# ATmega164PA register map
Vendor: Atmel; File version: 1.0
CPU: other r0p0, little endian, no MPU, no FPU, 4 interrupt priority bits
Registers are 8-bit, read-write, reset 0x0 unless marked. A register's access mark holds for its fields unless they carry their own. Offsets are from the block's base; [hi:lo] are bit positions.

## TC1 — Timer/Counter, 16-bit
Base 0x00800036
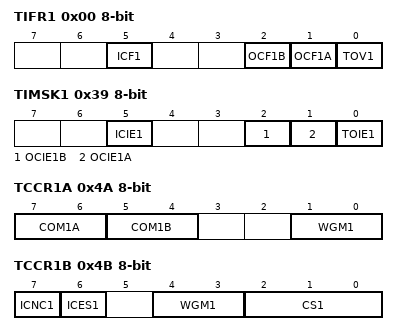
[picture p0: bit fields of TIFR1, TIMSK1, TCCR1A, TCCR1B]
0x00 TIFR1 — Timer/Counter Interrupt Flag register (read-only for debugger)
  [5] ICF1 — Timer/Counter1 Input Capture Flag
  [2] OCF1B — Timer/Counter1 Output Compare B Match Flag
  [1] OCF1A — Timer/Counter1 Output Compare A Match Flag
  [0] TOV1 — Timer/Counter1 Overflow Flag
0x39 TIMSK1 — Timer/Counter1 Interrupt Mask Register
  [5] ICIE1 — Timer/Counter1 Input Capture Interrupt Enable
  [2] OCIE1B — Timer/Counter1 Output Compare B Match Interrupt Enable
  [1] OCIE1A — Timer/Counter1 Output Compare A Match Interrupt Enable
  [0] TOIE1 — Timer/Counter1 Overflow Interrupt Enable
0x4A TCCR1A — Timer/Counter1 Control Register A
  [7:6] COM1A — Compare Output Mode 1A, bits
  [5:4] COM1B — Compare Output Mode 1B, bits
  [1:0] WGM1 — Pulse Width Modulator Select Bits
0x4B TCCR1B — Timer/Counter1 Control Register B
  [7] ICNC1 — Input Capture 1 Noise Canceler
  [6] ICES1 — Input Capture 1 Edge Select
  [4:3] WGM1 — Waveform Generation Mode Bits
  [2:0] CS1 — Clock Select1 bits
    0=NO_CLOCK_SOURCE_STOPPED; 1=RUNNING_NO_PRESCALING; 2=RUNNING_CLK_8; 3=RUNNING_CLK_64; 4=RUNNING_CLK_256; 5=RUNNING_CLK_1024; 6=RUNNING_EXTCLK_TN_FALLING_EDGE; 7=RUNNING_EXTCLK_TN_RISING_EDGE
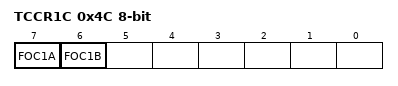
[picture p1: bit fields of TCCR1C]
0x4C TCCR1C — Timer/Counter1 Control Register C (write-only for debugger)
  [7] FOC1A — Force Output Compare for Channel A
  [6] FOC1B — Force Output Compare for Channel B
0x4E TCNT1 16-bit (reset mask 0xFF) — Timer/Counter1 Bytes
0x50 ICR1 16-bit (reset mask 0xFF) — Timer/Counter1 Input Capture Register Bytes
0x52 OCR1A 16-bit (reset mask 0xFF) — Timer/Counter1 Output Compare Register A Bytes
0x54 OCR1B 16-bit (reset mask 0xFF) — Timer/Counter1 Output Compare Register B Bytes

## TC2 — Timer/Counter, 8-bit Async
Base 0x00800037
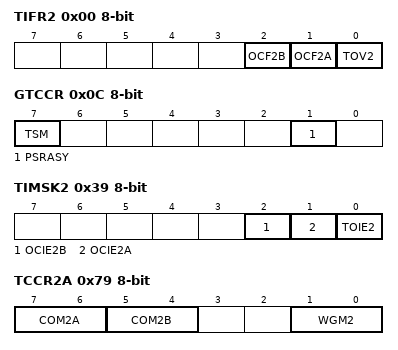
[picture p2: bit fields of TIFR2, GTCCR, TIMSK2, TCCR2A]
0x00 TIFR2 — Timer/Counter Interrupt Flag Register (read-only for debugger)
  [2] OCF2B — Output Compare Flag 2B
  [1] OCF2A — Output Compare Flag 2A
  [0] TOV2 — Timer/Counter2 Overflow Flag
0x0C GTCCR — General Timer Counter Control register
  [7] TSM — Timer/Counter Synchronization Mode
  [1] PSRASY — Prescaler Reset Timer/Counter2
0x39 TIMSK2 — Timer/Counter Interrupt Mask register
  [2] OCIE2B — Timer/Counter2 Output Compare Match B Interrupt Enable
  [1] OCIE2A — Timer/Counter2 Output Compare Match A Interrupt Enable
  [0] TOIE2 — Timer/Counter2 Overflow Interrupt Enable
0x79 TCCR2A — Timer/Counter2 Control Register A
  [7:6] COM2A — Compare Output Mode bits
  [5:4] COM2B — Compare Output Mode bits
  [1:0] WGM2 — Waveform Generation Mode
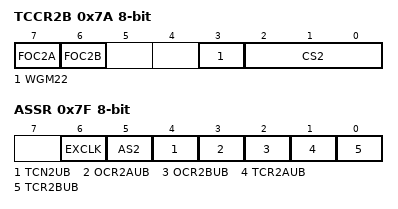
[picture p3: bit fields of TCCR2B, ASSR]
0x7A TCCR2B — Timer/Counter2 Control Register B
  [7] FOC2A — Force Output Compare A
  [6] FOC2B — Force Output Compare B
  [3] WGM22 — Waveform Generation Mode
  [2:0] CS2 — Clock Select bits
    0=NO_CLOCK_SOURCE_STOPPED; 1=RUNNING_NO_PRESCALING; 2=RUNNING_CLK_8; 3=RUNNING_CLK_32; 4=RUNNING_CLK_64; 5=RUNNING_CLK_128; 6=RUNNING_CLK_256; 7=RUNNING_CLK_1024
0x7B TCNT2 — Timer/Counter2
0x7C OCR2A — Timer/Counter2 Output Compare Register A
0x7D OCR2B — Timer/Counter2 Output Compare Register B
0x7F ASSR — Asynchronous Status Register
  [6] EXCLK — Enable External Clock Input
  [5] AS2 — Asynchronous Timer/Counter2
  [4] TCN2UB — Timer/Counter2 Update Busy
  [3] OCR2AUB — Output Compare Register2 Update Busy
  [2] OCR2BUB — Output Compare Register 2 Update Busy
  [1] TCR2AUB — Timer/Counter Control Register2 Update Busy
  [0] TCR2BUB — Timer/Counter Control Register2 Update Busy

## TWI — Two Wire Serial Interface
Base 0x008000B8
0x00 TWBR — TWI Bit Rate register
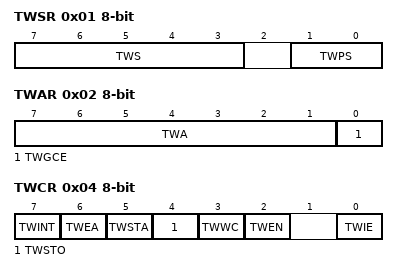
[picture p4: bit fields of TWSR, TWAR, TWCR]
0x01 TWSR — TWI Status Register
  [7:3] TWS — TWI Status
  [1:0] TWPS — TWI Prescaler
    0=1; 1=4; 2=16; 3=64
0x02 TWAR — TWI (Slave) Address register
  [7:1] TWA — TWI (Slave) Address register Bits
  [0] TWGCE — TWI General Call Recognition Enable Bit
0x03 TWDR — TWI Data register
0x04 TWCR — TWI Control Register (read-only for debugger)
  [7] TWINT — TWI Interrupt Flag
  [6] TWEA — TWI Enable Acknowledge Bit
  [5] TWSTA — TWI Start Condition Bit
  [4] TWSTO — TWI Stop Condition Bit
  [3] TWWC — TWI Write Collision Flag
  [2] TWEN — TWI Enable Bit
  [0] TWIE — TWI Interrupt Enable
0x05 TWAMR — TWI (Slave) Address Mask Register
  [7:1] TWAM

## USART0 — USART
Base 0x008000C0
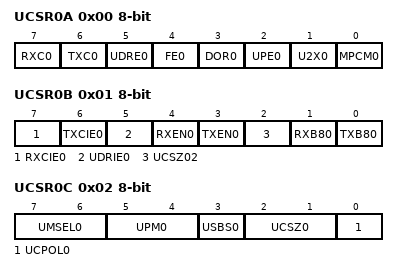
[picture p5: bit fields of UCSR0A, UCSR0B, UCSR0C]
0x00 UCSR0A — USART Control and Status Register A (read-only for debugger)
  [7] RXC0 ro — USART Receive Complete
  [6] TXC0 — USART Transmit Complete
  [5] UDRE0 ro — USART Data Register Empty
  [4] FE0 ro — Framing Error
  [3] DOR0 ro — Data overRun
  [2] UPE0 ro — Parity Error
  [1] U2X0 — Double the USART transmission speed
  [0] MPCM0 — Multi-processor Communication Mode
0x01 UCSR0B — USART Control and Status Register B
  [7] RXCIE0 — RX Complete Interrupt Enable
  [6] TXCIE0 — TX Complete Interrupt Enable
  [5] UDRIE0 — USART Data register Empty Interrupt Enable
  [4] RXEN0 — Receiver Enable
  [3] TXEN0 — Transmitter Enable
  [2] UCSZ02 — Character Size
  [1] RXB80 — Receive Data Bit 8
  [0] TXB80 — Transmit Data Bit 8
0x02 UCSR0C — USART Control and Status Register C
  [7:6] UMSEL0 — USART Mode Select
    0=ASYNCHRONOUS_USART; 1=SYNCHRONOUS_USART; 3=MASTER_SPI
  [5:4] UPM0 — Parity Mode Bits
    0=DISABLED; 2=ENABLED_EVEN_PARITY; 3=ENABLED_ODD_PARITY
  [3] USBS0 — Stop Bit Select
    0=1_BIT; 1=2_BIT
  [2:1] UCSZ0 — Character Size
  [0] UCPOL0 — Clock Polarity
0x04 UBRR0 16-bit (reset mask 0xFF) — USART Baud Rate Register Bytes
0x06 UDR0 — USART I/O Data Register (write-only for debugger)

## USART1 — USART
Base 0x008000C8
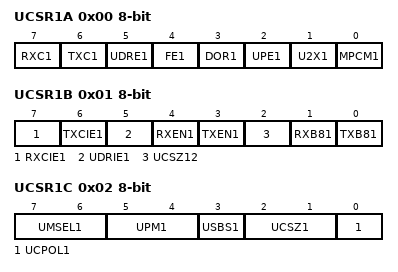
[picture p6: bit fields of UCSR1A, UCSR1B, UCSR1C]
0x00 UCSR1A — USART Control and Status Register A (read-only for debugger)
  [7] RXC1 — USART Receive Complete
  [6] TXC1 — USART Transmit Complete
  [5] UDRE1 — USART Data Register Empty
  [4] FE1 — Framing Error
  [3] DOR1 — Data overRun
  [2] UPE1 — Parity Error
  [1] U2X1 — Double the USART transmission speed
  [0] MPCM1 — Multi-processor Communication Mode
0x01 UCSR1B — USART Control and Status Register B
  [7] RXCIE1 — RX Complete Interrupt Enable
  [6] TXCIE1 — TX Complete Interrupt Enable
  [5] UDRIE1 — USART Data register Empty Interrupt Enable
  [4] RXEN1 — Receiver Enable
  [3] TXEN1 — Transmitter Enable
  [2] UCSZ12 — Character Size
  [1] RXB81 — Receive Data Bit 8
  [0] TXB81 — Transmit Data Bit 8
0x02 UCSR1C — USART Control and Status Register C
  [7:6] UMSEL1 — USART Mode Select
    0=ASYNCHRONOUS_USART; 1=SYNCHRONOUS_USART; 3=MASTER_SPI
  [5:4] UPM1 — Parity Mode Bits
    0=DISABLED; 2=ENABLED_EVEN_PARITY; 3=ENABLED_ODD_PARITY
  [3] USBS1 — Stop Bit Select
    0=1_BIT; 1=2_BIT
  [2:1] UCSZ1 — Character Size
  [0] UCPOL1 — Clock Polarity
0x04 UBRR1 16-bit (reset mask 0xFF) — USART Baud Rate Register Bytes
0x06 UDR1 — USART I/O Data Register (write-only for debugger)

## WDT — Watchdog Timer
Base 0x00800060
0x00 WDTCSR — Watchdog Timer Control Register (read-only for debugger)
  [7] WDIF — Watchdog Timeout Interrupt Flag
  [6] WDIE — Watchdog Timeout Interrupt Enable
  [4] WDCE — Watchdog Change Enable
  [3] WDE — Watch Dog Enable
  [5:0] WDP — Watchdog Timer Prescaler Bits
    0=OSCILLATOR_CYCLES_2K; 1=OSCILLATOR_CYCLES_4K; 2=OSCILLATOR_CYCLES_8K; 3=OSCILLATOR_CYCLES_16K; 4=OSCILLATOR_CYCLES_32K; 5=OSCILLATOR_CYCLES_64K; 6=OSCILLATOR_CYCLES_128K; 7=OSCILLATOR_CYCLES_256K
